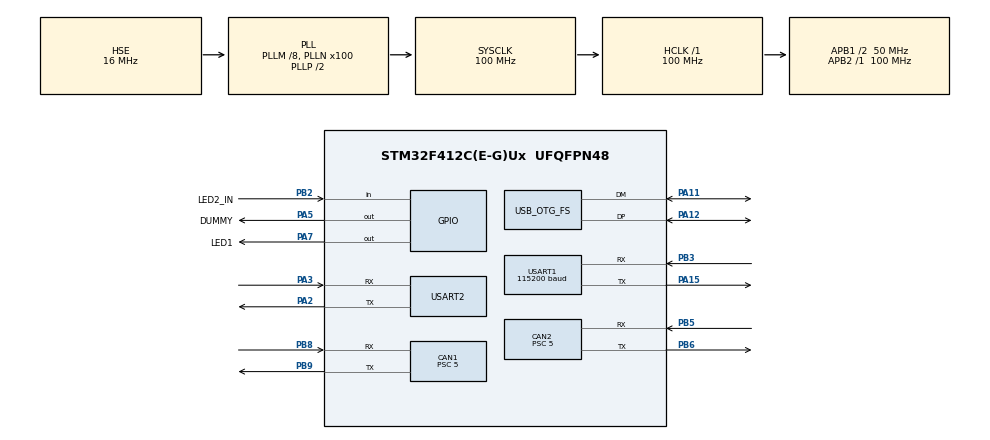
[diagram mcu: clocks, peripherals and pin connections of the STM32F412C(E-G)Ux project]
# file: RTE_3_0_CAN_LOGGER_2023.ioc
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CAN1.ABOM=ENABLE
CAN1.BS1=CAN_BS1_8TQ
CAN1.BS2=CAN_BS2_1TQ
CAN1.CalculateBaudRate=1000000
CAN1.CalculateTimeBit=1000
CAN1.CalculateTimeQuantum=100.0
CAN1.Prescaler=5
CAN2.ABOM=ENABLE
CAN2.BS1=CAN_BS1_8TQ
CAN2.BS2=CAN_BS2_1TQ
CAN2.CalculateBaudRate=1000000
CAN2.CalculateTimeBit=1000
CAN2.CalculateTimeQuantum=100.0
CAN2.Prescaler=5
Dma.Request0=USART2_RX
Dma.USART2_RX.0.Direction=DMA_PERIPH_TO_MEMORY
Dma.USART2_RX.0.FIFOMode=DMA_FIFOMODE_DISABLE
Dma.USART2_RX.0.Instance=DMA1_Stream5
Dma.USART2_RX.0.MemDataAlignment=DMA_MDATAALIGN_BYTE
Dma.USART2_RX.0.MemInc=DMA_MINC_ENABLE
Dma.USART2_RX.0.Mode=DMA_CIRCULAR
Dma.USART2_RX.0.PeriphDataAlignment=DMA_PDATAALIGN_BYTE
Dma.USART2_RX.0.PeriphInc=DMA_PINC_DISABLE
Dma.USART2_RX.0.Priority=DMA_PRIORITY_LOW
FATFS._FS_EXFAT=1
FATFS._MAX_SS=4096
FATFS._USE_LFN=1
Mcu.Family=STM32F4
Mcu.Name=STM32F412C(E-G)Ux
Mcu.Package=UFQFPN48
NVIC.CAN1_RX0_IRQn=true\:2\:0\:true\:false\:true\:true\:true\:true
NVIC.CAN1_SCE_IRQn=true\:2\:0\:true\:false\:true\:true\:true\:true
NVIC.CAN2_RX1_IRQn=true\:2\:0\:true\:false\:true\:true\:true\:true
NVIC.CAN2_SCE_IRQn=true\:2\:0\:true\:false\:true\:true\:true\:true
NVIC.DMA1_Stream5_IRQn=true\:4\:0\:true\:false\:true\:false\:true\:true
NVIC.OTG_FS_IRQn=true\:1\:0\:true\:false\:true\:false\:true\:true
NVIC.PriorityGroup=NVIC_PRIORITYGROUP_4
NVIC.TIM2_IRQn=true\:5\:0\:true\:false\:true\:true\:true\:true
NVIC.USART1_IRQn=true\:3\:0\:true\:false\:true\:true\:true\:true
NVIC.USART2_IRQn=true\:4\:0\:true\:false\:true\:true\:true\:true
PA11.Mode=Host_Only
PA11.Signal=USB_OTG_FS_DM
PA12.Mode=Host_Only
PA12.Signal=USB_OTG_FS_DP
PA13.Mode=Serial_Wire
PA13.Signal=SYS_JTMS-SWDIO
PA14.Mode=Serial_Wire
PA14.Signal=SYS_JTCK-SWCLK
PA15.Mode=Asynchronous
PA15.Signal=USART1_TX
PA2.Mode=Asynchronous
PA2.Signal=USART2_TX
PA3.Mode=Asynchronous
PA3.Signal=USART2_RX
PA5.GPIO_Label=DUMMY
PA5.Signal=GPIO_Output
PA7.GPIO_Label=LED1
PA7.Signal=GPIO_Output
PB2.GPIO_Label=LED2_IN
PB2.GPIO_PuPd=GPIO_PULLUP
PB2.Signal=GPIO_Input
PB3.Mode=Asynchronous
PB3.Signal=USART1_RX
PB5.Mode=CAN_Activate
PB5.Signal=CAN2_RX
PB6.Mode=CAN_Activate
PB6.Signal=CAN2_TX
PB8.Mode=CAN_Activate
PB8.Signal=CAN1_RX
PB9.Mode=CAN_Activate
PB9.Signal=CAN1_TX
PC14-OSC32_IN.Mode=LSE-External-Oscillator
PC14-OSC32_IN.Signal=RCC_OSC32_IN
PC15-OSC32_OUT.Mode=LSE-External-Oscillator
PC15-OSC32_OUT.Signal=RCC_OSC32_OUT
PH0\ -\ OSC_IN.Mode=HSE-External-Clock-Source
PH0\ -\ OSC_IN.Signal=RCC_OSC_IN
PH1\ -\ OSC_OUT.Mode=HSE-External-Clock-Source
PH1\ -\ OSC_OUT.Signal=RCC_OSC_OUT
ProjectManager.HeapSize=0x1000
ProjectManager.StackSize=0x1600
ProjectManager.TargetToolchain=STM32CubeIDE
RCC.AHBFreq_Value=100000000
RCC.APB1CLKDivider=RCC_HCLK_DIV2
RCC.APB1Freq_Value=50000000
RCC.APB1TimFreq_Value=100000000
RCC.APB2Freq_Value=100000000
RCC.APB2TimFreq_Value=100000000
RCC.CortexFreq_Value=100000000
RCC.HCLKFreq_Value=100000000
RCC.HSE_VALUE=16000000
RCC.PLLI2SM=8
RCC.PLLI2SN=72
RCC.PLLI2SQ=3
RCC.PLLM=8
RCC.PLLN=100
RCC.PLLQ=3
RCC.RCC_RTC_Clock_Source=RCC_RTCCLKSOURCE_LSE
RCC.RCC_RTC_Clock_SourceVirtual=RCC_RTCCLKSOURCE_LSE
RCC.SYSCLKFreq_VALUE=100000000
RCC.SYSCLKSource=RCC_SYSCLKSOURCE_PLLCLK
RCC.USBCLockSelection=RCC_CLK48CLKSOURCE_PLLI2SQ
RCC.USBFreq_Value=48000000
RCC.VCOOutputFreq_Value=200000000
RTC.Date=11
RTC.Format=RTC_FORMAT_BIN
RTC.Hours=11
RTC.Month=RTC_MONTH_MAY
RTC.WeekDay=RTC_WEEKDAY_THURSDAY
RTC.Year=22
TIM2.Prescaler=99
USART1.BaudRate=115200
USART1.VirtualMode=VM_ASYNC
USART2.VirtualMode=VM_ASYNC
USB_HOST.BSP.number=1
USB_HOST.USBH_HandleTypeDef=hUsbHostFS
USB_HOST.VirtualModeFS=Msc
USB_HOST0.BSP.STBoard=false
USB_HOST0.BSP.api=Unknown
USB_HOST0.BSP.instance=PA5
USB_HOST0.BSP.ip=GPIO
USB_HOST0.BSP.mode=Output
USB_HOST0.BSP.name=Drive_VBUS_FS
USB_HOST0.BSP.solution=PA5
USB_OTG_FS.VirtualMode=Host_Only
USB_OTG_FS.phy_itface=HCD_PHY_EMBEDDED
VP_FATFS_VS_USB.Mode=USB
VP_RTC_VS_RTC_Activate.Mode=RTC_Enabled
VP_RTC_VS_RTC_Calendar.Mode=RTC_Calendar
VP_TIM2_VS_ClockSourceINT.Mode=Internal
VP_USB_HOST_VS_USB_HOST_MSC_FS.Mode=MSC_FS
board=custom

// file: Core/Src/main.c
/* USER CODE BEGIN Header */
/**
 ******************************************************************************
 * @file           : main.c
 * @brief          : Main program body
 ******************************************************************************
 * @attention
 *
 * Copyright (c) 2023 STMicroelectronics.
 * All rights reserved.
 *
 * This software is licensed under terms that can be found in the LICENSE file
 * in the root directory of this software component.
 * If no LICENSE file comes with this software, it is provided AS-IS.
 *
 ******************************************************************************
 */
/* USER CODE END Header */
#include "main.h"
#include "fatfs.h"
#include "usb_host.h"

/* USER CODE BEGIN Includes */
#include "App.h"
#include "watchdog.h"
/* USER CODE END Includes */

CAN_HandleTypeDef hcan1;
CAN_HandleTypeDef hcan2;

RTC_HandleTypeDef hrtc;

TIM_HandleTypeDef htim2;

UART_HandleTypeDef huart1;
UART_HandleTypeDef huart2;
DMA_HandleTypeDef hdma_usart2_rx;

void SystemClock_Config(void);
static void MX_GPIO_Init(void);
static void MX_DMA_Init(void);
static void MX_USART2_UART_Init(void);
static void MX_RTC_Init(void);
static void MX_TIM2_Init(void);
static void MX_CAN1_Init(void);
static void MX_CAN2_Init(void);
static void MX_USART1_UART_Init(void);
void MX_USB_HOST_Process(void);

int main(void)
{

  /* MCU Configuration--------------------------------------------------------*/

  /* Reset of all peripherals, Initializes the Flash interface and the Systick. */
  HAL_Init();

  /* Configure the system clock */
  SystemClock_Config();

  /* USER CODE BEGIN SysInit */
  WatchdogInit();
  /* USER CODE END SysInit */

  /* Initialize all configured peripherals */
  MX_GPIO_Init();
  MX_DMA_Init();
  MX_USB_HOST_Init();
  MX_FATFS_Init();
  MX_USART2_UART_Init();
  MX_RTC_Init();
  MX_TIM2_Init();
  MX_CAN1_Init();
  MX_CAN2_Init();
  MX_USART1_UART_Init();

  /* Infinite loop */
  /* USER CODE BEGIN WHILE */

  AppInit();
  AppRun();
	while (1) {
    /* USER CODE END WHILE */
    MX_USB_HOST_Process();

	}
}

void SystemClock_Config(void)
{
  RCC_OscInitTypeDef RCC_OscInitStruct = {0};
  RCC_ClkInitTypeDef RCC_ClkInitStruct = {0};

  /** Configure the main internal regulator output voltage
  */
  __HAL_RCC_PWR_CLK_ENABLE();
  __HAL_PWR_VOLTAGESCALING_CONFIG(PWR_REGULATOR_VOLTAGE_SCALE1);

  /** Initializes the RCC Oscillators according to the specified parameters
  * in the RCC_OscInitTypeDef structure.
  */
  RCC_OscInitStruct.OscillatorType = RCC_OSCILLATORTYPE_HSE|RCC_OSCILLATORTYPE_LSE;
  RCC_OscInitStruct.HSEState = RCC_HSE_BYPASS;
  RCC_OscInitStruct.LSEState = RCC_LSE_ON;
  RCC_OscInitStruct.PLL.PLLState = RCC_PLL_ON;
  RCC_OscInitStruct.PLL.PLLSource = RCC_PLLSOURCE_HSE;
  RCC_OscInitStruct.PLL.PLLM = 8;
  RCC_OscInitStruct.PLL.PLLN = 100;
  RCC_OscInitStruct.PLL.PLLP = RCC_PLLP_DIV2;
  RCC_OscInitStruct.PLL.PLLQ = 3;
  RCC_OscInitStruct.PLL.PLLR = 2;
  if (HAL_RCC_OscConfig(&RCC_OscInitStruct) != HAL_OK)
  {
    Error_Handler();
  }

  /** Initializes the CPU, AHB and APB buses clocks
  */
  RCC_ClkInitStruct.ClockType = RCC_CLOCKTYPE_HCLK|RCC_CLOCKTYPE_SYSCLK
                              |RCC_CLOCKTYPE_PCLK1|RCC_CLOCKTYPE_PCLK2;
  RCC_ClkInitStruct.SYSCLKSource = RCC_SYSCLKSOURCE_PLLCLK;
  RCC_ClkInitStruct.AHBCLKDivider = RCC_SYSCLK_DIV1;
  RCC_ClkInitStruct.APB1CLKDivider = RCC_HCLK_DIV2;
  RCC_ClkInitStruct.APB2CLKDivider = RCC_HCLK_DIV1;

  if (HAL_RCC_ClockConfig(&RCC_ClkInitStruct, FLASH_LATENCY_3) != HAL_OK)
  {
    Error_Handler();
  }
}

static void MX_CAN1_Init(void)
{

  hcan1.Instance = CAN1;
  hcan1.Init.Prescaler = 5;
  hcan1.Init.Mode = CAN_MODE_NORMAL;
  hcan1.Init.SyncJumpWidth = CAN_SJW_1TQ;
  hcan1.Init.TimeSeg1 = CAN_BS1_8TQ;
  hcan1.Init.TimeSeg2 = CAN_BS2_1TQ;
  hcan1.Init.TimeTriggeredMode = DISABLE;
  hcan1.Init.AutoBusOff = ENABLE;
  hcan1.Init.AutoWakeUp = DISABLE;
  hcan1.Init.AutoRetransmission = DISABLE;
  hcan1.Init.ReceiveFifoLocked = DISABLE;
  hcan1.Init.TransmitFifoPriority = DISABLE;
  if (HAL_CAN_Init(&hcan1) != HAL_OK)
  {
    Error_Handler();
  }

}

static void MX_CAN2_Init(void)
{

  hcan2.Instance = CAN2;
  hcan2.Init.Prescaler = 5;
  hcan2.Init.Mode = CAN_MODE_NORMAL;
  hcan2.Init.SyncJumpWidth = CAN_SJW_1TQ;
  hcan2.Init.TimeSeg1 = CAN_BS1_8TQ;
  hcan2.Init.TimeSeg2 = CAN_BS2_1TQ;
  hcan2.Init.TimeTriggeredMode = DISABLE;
  hcan2.Init.AutoBusOff = ENABLE;
  hcan2.Init.AutoWakeUp = DISABLE;
  hcan2.Init.AutoRetransmission = DISABLE;
  hcan2.Init.ReceiveFifoLocked = DISABLE;
  hcan2.Init.TransmitFifoPriority = DISABLE;
  if (HAL_CAN_Init(&hcan2) != HAL_OK)
  {
    Error_Handler();
  }

}

static void MX_RTC_Init(void)
{

  RTC_TimeTypeDef sTime = {0};
  RTC_DateTypeDef sDate = {0};

  /** Initialize RTC Only
  */
  hrtc.Instance = RTC;
  hrtc.Init.HourFormat = RTC_HOURFORMAT_24;
  hrtc.Init.AsynchPrediv = 127;
  hrtc.Init.SynchPrediv = 255;
  hrtc.Init.OutPut = RTC_OUTPUT_DISABLE;
  hrtc.Init.OutPutPolarity = RTC_OUTPUT_POLARITY_HIGH;
  hrtc.Init.OutPutType = RTC_OUTPUT_TYPE_OPENDRAIN;
  if (HAL_RTC_Init(&hrtc) != HAL_OK)
  {
    Error_Handler();
  }

  /* USER CODE BEGIN Check_RTC_BKUP */
  //
  //	You have to do not let Init code to reinitialize Time and Date in RTC.
  //	It's "a bug" in HAL widely described and complain on forums.
  //	That causes every MCU restart the time and date will be same as you configured in CubeMX.
  //	All you have to do is just return before init time/date in this user section.
  //
                         return;
  /* USER CODE END Check_RTC_BKUP */

  /** Initialize RTC and set the Time and Date
  */
  sTime.Hours = 11;
  sTime.Minutes = 0;
  sTime.Seconds = 0;
  sTime.DayLightSaving = RTC_DAYLIGHTSAVING_NONE;
  sTime.StoreOperation = RTC_STOREOPERATION_RESET;
  if (HAL_RTC_SetTime(&hrtc, &sTime, RTC_FORMAT_BIN) != HAL_OK)
  {
    Error_Handler();
  }
  sDate.WeekDay = RTC_WEEKDAY_THURSDAY;
  sDate.Month = RTC_MONTH_MAY;
  sDate.Date = 11;
  sDate.Year = 22;

  if (HAL_RTC_SetDate(&hrtc, &sDate, RTC_FORMAT_BIN) != HAL_OK)
  {
    Error_Handler();
  }

}

static void MX_TIM2_Init(void)
{

  TIM_ClockConfigTypeDef sClockSourceConfig = {0};
  TIM_MasterConfigTypeDef sMasterConfig = {0};

  htim2.Instance = TIM2;
  htim2.Init.Prescaler = 99;
  htim2.Init.CounterMode = TIM_COUNTERMODE_UP;
  htim2.Init.Period = 4294967295;
  htim2.Init.ClockDivision = TIM_CLOCKDIVISION_DIV1;
  htim2.Init.AutoReloadPreload = TIM_AUTORELOAD_PRELOAD_DISABLE;
  if (HAL_TIM_Base_Init(&htim2) != HAL_OK)
  {
    Error_Handler();
  }
  sClockSourceConfig.ClockSource = TIM_CLOCKSOURCE_INTERNAL;
  if (HAL_TIM_ConfigClockSource(&htim2, &sClockSourceConfig) != HAL_OK)
  {
    Error_Handler();
  }
  sMasterConfig.MasterOutputTrigger = TIM_TRGO_RESET;
  sMasterConfig.MasterSlaveMode = TIM_MASTERSLAVEMODE_DISABLE;
  if (HAL_TIMEx_MasterConfigSynchronization(&htim2, &sMasterConfig) != HAL_OK)
  {
    Error_Handler();
  }

}

static void MX_USART1_UART_Init(void)
{

  huart1.Instance = USART1;
  huart1.Init.BaudRate = 115200;
  huart1.Init.WordLength = UART_WORDLENGTH_8B;
  huart1.Init.StopBits = UART_STOPBITS_1;
  huart1.Init.Parity = UART_PARITY_NONE;
  huart1.Init.Mode = UART_MODE_TX_RX;
  huart1.Init.HwFlowCtl = UART_HWCONTROL_NONE;
  huart1.Init.OverSampling = UART_OVERSAMPLING_16;
  if (HAL_UART_Init(&huart1) != HAL_OK)
  {
    Error_Handler();
  }

}

static void MX_USART2_UART_Init(void)
{

  huart2.Instance = USART2;
  huart2.Init.BaudRate = 115200;
  huart2.Init.WordLength = UART_WORDLENGTH_8B;
  huart2.Init.StopBits = UART_STOPBITS_1;
  huart2.Init.Parity = UART_PARITY_NONE;
  huart2.Init.Mode = UART_MODE_TX_RX;
  huart2.Init.HwFlowCtl = UART_HWCONTROL_NONE;
  huart2.Init.OverSampling = UART_OVERSAMPLING_16;
  if (HAL_UART_Init(&huart2) != HAL_OK)
  {
    Error_Handler();
  }

}

static void MX_DMA_Init(void)
{

  /* DMA controller clock enable */
  __HAL_RCC_DMA1_CLK_ENABLE();

  /* DMA interrupt init */
  /* DMA1_Stream5_IRQn interrupt configuration */
  HAL_NVIC_SetPriority(DMA1_Stream5_IRQn, 4, 0);
  HAL_NVIC_EnableIRQ(DMA1_Stream5_IRQn);

}

static void MX_GPIO_Init(void)
{
  GPIO_InitTypeDef GPIO_InitStruct = {0};

  /* GPIO Ports Clock Enable */
  __HAL_RCC_GPIOC_CLK_ENABLE();
  __HAL_RCC_GPIOH_CLK_ENABLE();
  __HAL_RCC_GPIOA_CLK_ENABLE();
  __HAL_RCC_GPIOB_CLK_ENABLE();

  /*Configure GPIO pin Output Level */
  HAL_GPIO_WritePin(GPIOA, DUMMY_Pin|LED1_Pin, GPIO_PIN_RESET);

  /*Configure GPIO pin : PC13 */
  GPIO_InitStruct.Pin = GPIO_PIN_13;
  GPIO_InitStruct.Mode = GPIO_MODE_ANALOG;
  GPIO_InitStruct.Pull = GPIO_NOPULL;
  HAL_GPIO_Init(GPIOC, &GPIO_InitStruct);

  /*Configure GPIO pins : PA0 PA1 PA4 PA6
                           PA8 PA9 PA10 */
  GPIO_InitStruct.Pin = GPIO_PIN_0|GPIO_PIN_1|GPIO_PIN_4|GPIO_PIN_6
                          |GPIO_PIN_8|GPIO_PIN_9|GPIO_PIN_10;
  GPIO_InitStruct.Mode = GPIO_MODE_ANALOG;
  GPIO_InitStruct.Pull = GPIO_NOPULL;
  HAL_GPIO_Init(GPIOA, &GPIO_InitStruct);

  /*Configure GPIO pins : DUMMY_Pin LED1_Pin */
  GPIO_InitStruct.Pin = DUMMY_Pin|LED1_Pin;
  GPIO_InitStruct.Mode = GPIO_MODE_OUTPUT_PP;
  GPIO_InitStruct.Pull = GPIO_NOPULL;
  GPIO_InitStruct.Speed = GPIO_SPEED_FREQ_LOW;
  HAL_GPIO_Init(GPIOA, &GPIO_InitStruct);

  /*Configure GPIO pins : PB0 PB1 PB10 PB12
                           PB13 PB14 PB15 PB4
                           PB7 */
  GPIO_InitStruct.Pin = GPIO_PIN_0|GPIO_PIN_1|GPIO_PIN_10|GPIO_PIN_12
                          |GPIO_PIN_13|GPIO_PIN_14|GPIO_PIN_15|GPIO_PIN_4
                          |GPIO_PIN_7;
  GPIO_InitStruct.Mode = GPIO_MODE_ANALOG;
  GPIO_InitStruct.Pull = GPIO_NOPULL;
  HAL_GPIO_Init(GPIOB, &GPIO_InitStruct);

  /*Configure GPIO pin : LED2_IN_Pin */
  GPIO_InitStruct.Pin = LED2_IN_Pin;
  GPIO_InitStruct.Mode = GPIO_MODE_INPUT;
  GPIO_InitStruct.Pull = GPIO_PULLUP;
  HAL_GPIO_Init(LED2_IN_GPIO_Port, &GPIO_InitStruct);

}

void Error_Handler(void)
{
  /* USER CODE BEGIN Error_Handler_Debug */
	/* User can add his own implementation to report the HAL error return state */
	__disable_irq();
#ifndef LOGGER_DEVELOP
	NVIC_SystemReset();
#endif
	while (1) {
		__NOP();
	}
  /* USER CODE END Error_Handler_Debug */
}
